VERSION ""

NS_ :

BS_:

BU_: XXX

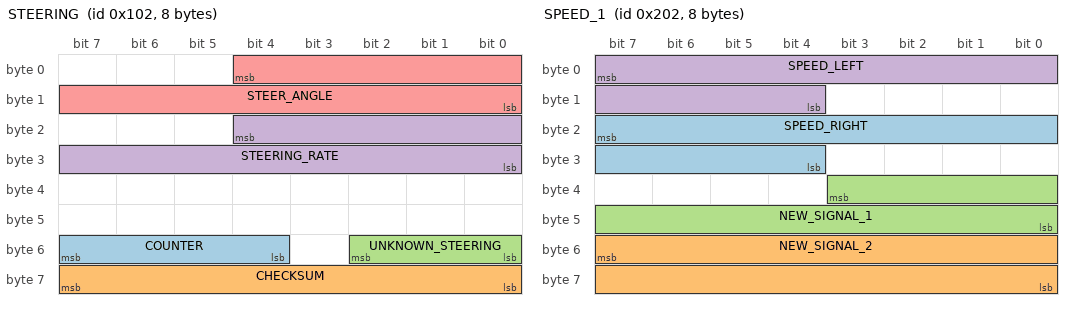
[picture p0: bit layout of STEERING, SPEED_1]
BO_ 258 STEERING: 8 XXX
 SG_ COUNTER : 55|4@0+ (1,0) [0|15] "" XXX
 SG_ CHECKSUM : 63|8@0+ (1,0) [0|255] "" XXX
 SG_ UNKNOWN_STEERING : 50|3@0+ (1,0) [0|15] "" XXX
 SG_ STEERING_RATE : 20|13@0+ (0.3187251,-1305.498) [0|8191] "deg/s" XXX
 SG_ STEER_ANGLE : 4|13@0+ (0.3187251,-1307.888) [-360|360] "deg" XXX

BO_ 514 SPEED_1: 8 XXX
 SG_ SPEED_RIGHT : 23|12@0+ (0.071028,0) [0|1023] "m/s" XXX
 SG_ NEW_SIGNAL_2 : 55|16@0+ (1,0) [0|65535] "" XXX
 SG_ NEW_SIGNAL_1 : 35|12@0+ (1,0) [0|63] "" XXX
 SG_ SPEED_LEFT : 7|12@0+ (0.071028,0) [0|65535] "m/s" XXX

BO_ 653 BRAKE_MODULE: 2 XXX
 SG_ BRAKE_PRESSURE : 15|8@0+ (1,0) [0|255] "" XXX
 SG_ BRAKE_PRESSED : 4|1@0+ (1,0) [0|4] "" XXX

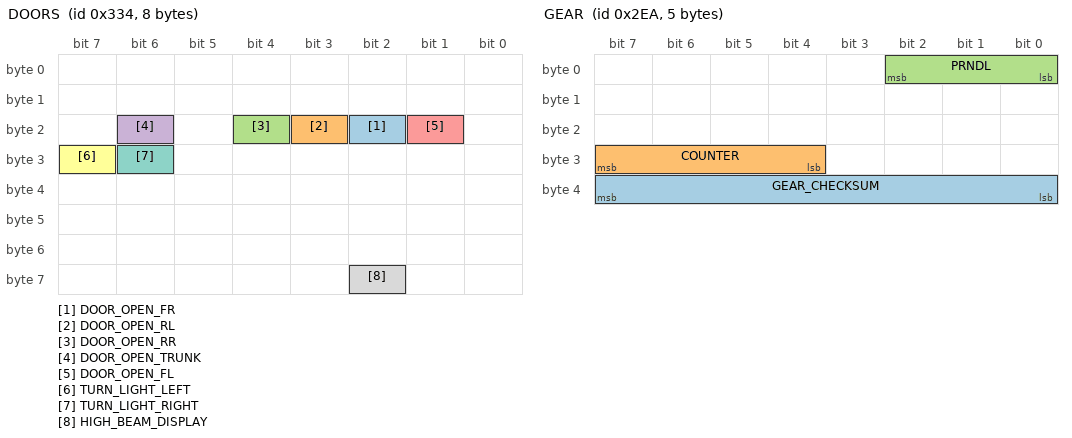
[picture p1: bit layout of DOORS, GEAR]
BO_ 820 DOORS: 8 XXX
 SG_ DOOR_OPEN_FR : 18|1@0+ (1,0) [0|1] "" XXX
 SG_ DOOR_OPEN_RL : 19|1@0+ (1,0) [0|1] "" XXX
 SG_ DOOR_OPEN_RR : 20|1@0+ (1,0) [0|1] "" XXX
 SG_ DOOR_OPEN_TRUNK : 22|1@0+ (1,0) [0|1] "" XXX
 SG_ DOOR_OPEN_FL : 17|1@0+ (1,0) [0|1] "" XXX
 SG_ TURN_LIGHT_LEFT : 31|1@0+ (1,0) [0|1] "" XXX
 SG_ TURN_LIGHT_RIGHT : 30|1@0+ (1,0) [0|1] "" XXX
 SG_ HIGH_BEAM_DISPLAY : 58|1@0+ (1,0) [0|1] "" XXX

BO_ 746 GEAR: 5 XXX
 SG_ GEAR_CHECKSUM : 39|8@0+ (1,0) [0|255] "" XXX
 SG_ COUNTER : 31|4@0+ (1,0) [0|15] "" XXX
 SG_ PRNDL : 2|3@0+ (1,0) [0|7] "" XXX

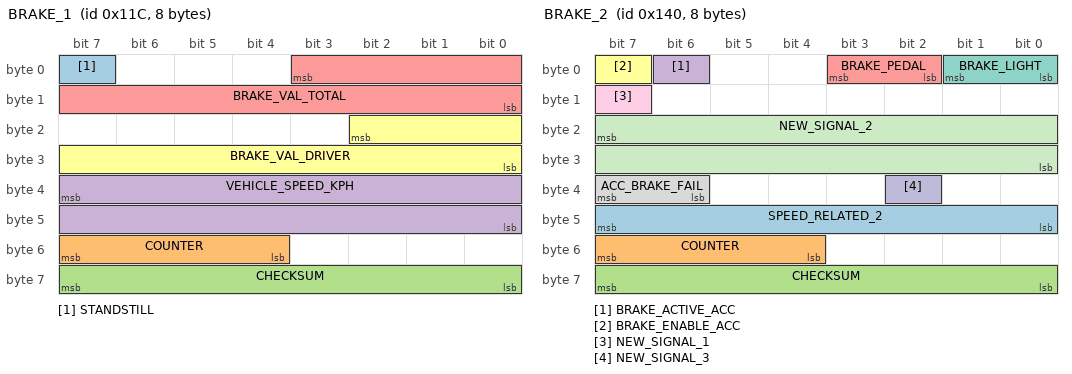
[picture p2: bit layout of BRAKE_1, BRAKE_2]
BO_ 284 BRAKE_1: 8 XXX
 SG_ STANDSTILL : 7|1@0+ (1,0) [0|1] "" XXX
 SG_ COUNTER : 55|4@0+ (1,0) [0|15] "" XXX
 SG_ CHECKSUM : 63|8@0+ (1,0) [0|255] "" XXX
 SG_ VEHICLE_SPEED_KPH : 39|16@0+ (0.0078125,0) [0|511.984375] "kph" XXX
 SG_ BRAKE_VAL_TOTAL : 3|12@0+ (1,0) [0|255] "" XXX
 SG_ BRAKE_VAL_DRIVER : 18|11@0+ (1,0) [0|255] "" XXX

BO_ 320 BRAKE_2: 8 XXX
 SG_ SPEED_RELATED_2 : 47|8@0+ (1,0) [0|63] "" XXX
 SG_ COUNTER : 55|4@0+ (1,0) [0|15] "" XXX
 SG_ CHECKSUM : 63|8@0+ (1,0) [0|255] "" XXX
 SG_ BRAKE_ACTIVE_ACC : 6|1@0+ (1,0) [0|3] "" XXX
 SG_ BRAKE_PEDAL : 2|2@1+ (1,0) [0|3] "" XXX
 SG_ BRAKE_ENABLE_ACC : 7|1@0+ (1,0) [0|1] "" XXX
 SG_ BRAKE_LIGHT : 1|2@0+ (1,0) [0|7] "" XXX
 SG_ ACC_BRAKE_FAIL : 39|2@0+ (1,0) [0|3] "" XXX
 SG_ NEW_SIGNAL_1 : 15|1@0+ (1,0) [0|255] "" XXX
 SG_ NEW_SIGNAL_3 : 34|1@0+ (1,0) [0|63] "" XXX
 SG_ NEW_SIGNAL_2 : 23|16@0+ (1,0) [0|65535] "" XXX

BO_ 736 TRIP: 8 XXX
 SG_ COUNTER : 7|16@0+ (1,0) [0|65535] "Meters" XXX
 SG_ COUNTER_2 : 23|16@0+ (1,0) [0|65535] "Meters" XXX

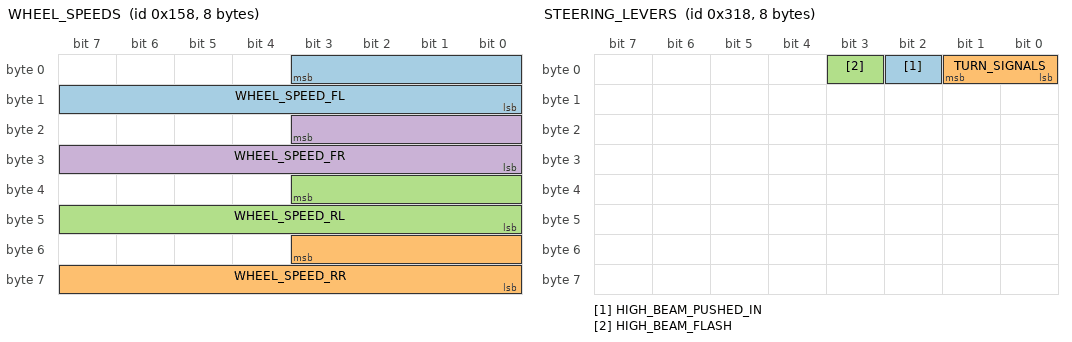
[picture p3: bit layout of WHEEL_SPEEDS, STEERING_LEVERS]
BO_ 344 WHEEL_SPEEDS: 8 XXX
 SG_ WHEEL_SPEED_FL : 3|12@0+ (0.0189408,0) [0|65535] "m/s" XXX
 SG_ WHEEL_SPEED_RR : 51|12@0+ (0.0189408,0) [0|255] "m/s" XXX
 SG_ WHEEL_SPEED_RL : 35|12@0+ (0.0189408,0) [0|3] "m/s" XXX
 SG_ WHEEL_SPEED_FR : 19|12@0+ (0.0189408,0) [0|255] "m/s" XXX

BO_ 792 STEERING_LEVERS: 8 XXX
 SG_ HIGH_BEAM_PUSHED_IN : 2|1@0+ (1,0) [0|3] "" XXX
 SG_ TURN_SIGNALS : 1|2@0+ (1,0) [0|3] "" XXX
 SG_ HIGH_BEAM_FLASH : 3|1@0+ (1,0) [0|3] "" XXX

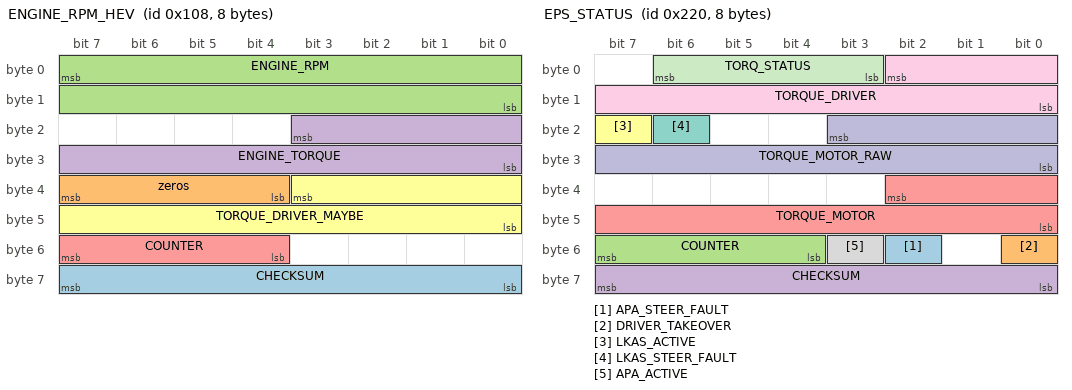
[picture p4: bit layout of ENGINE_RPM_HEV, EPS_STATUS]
BO_ 264 ENGINE_RPM_HEV: 8 XXX
 SG_ CHECKSUM : 63|8@0+ (1,0) [0|255] "" XXX
 SG_ zeros : 39|4@0+ (1,0) [0|4095] "" XXX
 SG_ ENGINE_RPM : 7|16@0+ (1,0) [0|65535] "" XXX
 SG_ ENGINE_TORQUE : 19|12@0+ (0.25,-500) [0|65535] "Nm" XXX
 SG_ COUNTER : 55|4@0+ (1,0) [0|15] "" XXX
 SG_ TORQUE_DRIVER_MAYBE : 35|12@0+ (0.25,-500) [0|1] "" XXX

BO_ 464 SEATBELT_STATUS: 8 XXX
 SG_ SEATBELT_DRIVER_UNLATCHED : 13|1@0+ (1,0) [0|1] "" XXX

BO_ 544 EPS_STATUS: 8 XXX
 SG_ APA_STEER_FAULT : 50|1@0+ (1,0) [0|1] "" XXX
 SG_ DRIVER_TAKEOVER : 48|1@0+ (1,0) [0|1] "" XXX
 SG_ COUNTER : 55|4@0+ (1,0) [0|15] "" XXX
 SG_ CHECKSUM : 63|8@0+ (1,0) [0|255] "" XXX
 SG_ TORQUE_MOTOR : 34|11@0+ (1,-1024) [0|1] "" XXX
 SG_ LKAS_ACTIVE : 23|1@0+ (1,0) [0|15] "" XXX
 SG_ LKAS_STEER_FAULT : 22|1@0+ (1,0) [0|1] "" XXX
 SG_ APA_ACTIVE : 51|1@0+ (1,0) [0|1] "" XXX
 SG_ TORQUE_DRIVER : 2|11@0+ (1,-1024) [0|1] "" XXX
 SG_ TORQUE_MOTOR_RAW : 19|12@0+ (1,-2000) [0|1] "" XXX
 SG_ TORQ_STATUS : 6|4@0+ (1,0) [0|15] "" XXX

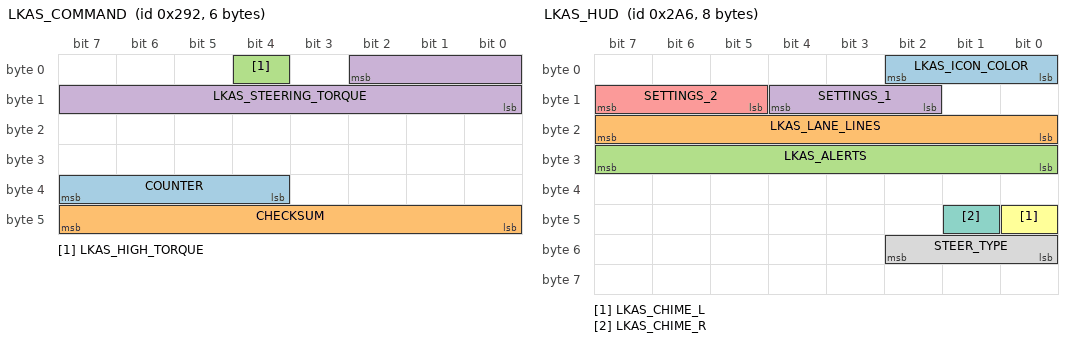
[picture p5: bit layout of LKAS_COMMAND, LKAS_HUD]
BO_ 658 LKAS_COMMAND: 6 XXX
 SG_ COUNTER : 39|4@0+ (1,0) [0|15] "" XXX
 SG_ CHECKSUM : 47|8@0+ (1,0) [0|255] "" XXX
 SG_ LKAS_HIGH_TORQUE : 4|1@0+ (1,0) [0|1] "" XXX
 SG_ LKAS_STEERING_TORQUE : 2|11@0+ (1,-1024) [0|1] "" XXX

BO_ 678 LKAS_HUD: 8 XXX
 SG_ LKAS_ICON_COLOR : 2|3@0+ (1,0) [0|3] "" XXX
 SG_ LKAS_LANE_LINES : 23|8@0+ (1,0) [0|1] "" XXX
 SG_ LKAS_ALERTS : 31|8@0+ (1,0) [0|1] "" XXX
 SG_ SETTINGS_1 : 12|3@0+ (1,0) [0|7] "" XXX
 SG_ SETTINGS_2 : 15|3@0+ (1,0) [0|31] "" XXX
 SG_ LKAS_CHIME_L : 40|1@0+ (1,0) [0|1] "" XXX
 SG_ LKAS_CHIME_R : 41|1@1+ (1,0) [0|3] "" XXX
 SG_ STEER_TYPE : 48|3@1+ (1,0) [0|3] "" XXX

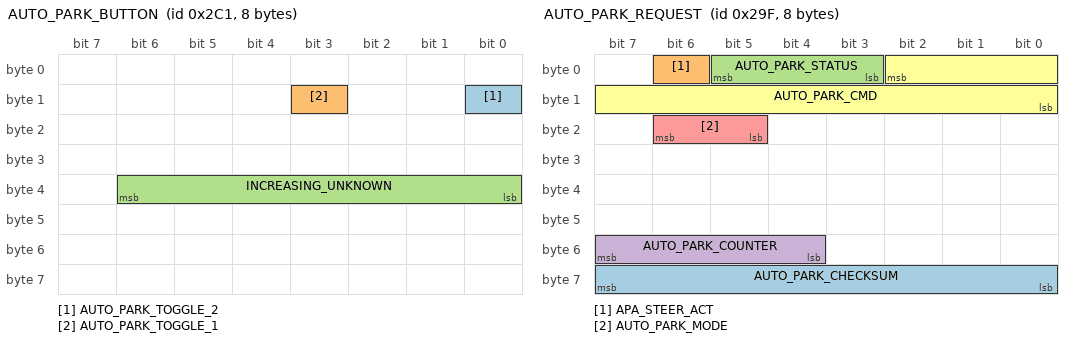
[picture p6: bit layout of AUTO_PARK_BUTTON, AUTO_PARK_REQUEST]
BO_ 705 AUTO_PARK_BUTTON: 8 XXX
 SG_ AUTO_PARK_TOGGLE_2 : 8|1@0+ (1,0) [0|1] "" XXX
 SG_ AUTO_PARK_TOGGLE_1 : 11|1@0+ (1,0) [0|1] "" XXX
 SG_ INCREASING_UNKNOWN : 38|7@0+ (1,0) [0|15] "" XXX

BO_ 719 AUTO_PARK_SIGNALS_1: 8 XXX
 SG_ AUTO_PARK_UNKNOWN_1 : 7|16@0+ (1,0) [0|31] "" XXX

BO_ 671 AUTO_PARK_REQUEST: 8 XXX
 SG_ AUTO_PARK_CHECKSUM : 63|8@0+ (1,0) [0|255] "" XXX
 SG_ APA_STEER_ACT : 6|1@0+ (1,0) [0|1] "" XXX
 SG_ AUTO_PARK_STATUS : 5|3@0+ (1,0) [0|15] "" XXX
 SG_ AUTO_PARK_COUNTER : 55|4@0+ (1,0) [0|15] "" XXX
 SG_ AUTO_PARK_MODE : 22|2@0+ (1,0) [0|3] "" XXX
 SG_ AUTO_PARK_CMD : 2|11@0+ (1,-1024) [0|1] "NM" XXX

BO_ 784 AUTO_PARK_LESS_INTERESTING: 8 XXX
 SG_ INCREASING_UNKNOWN : 55|8@0+ (1,0) [0|7] "" XXX
 SG_ AUTO_PARK_PERPENDICULAR_2 : 61|1@0+ (1,0) [0|255] "" XXX

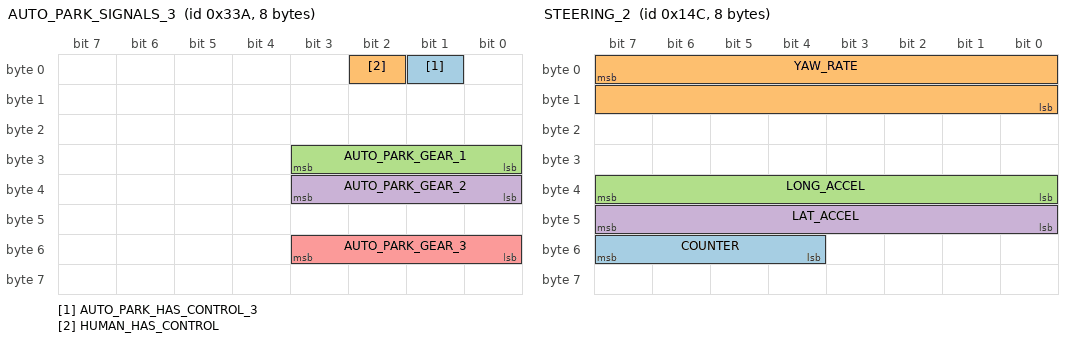
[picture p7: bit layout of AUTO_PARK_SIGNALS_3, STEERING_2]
BO_ 826 AUTO_PARK_SIGNALS_3: 8 XXX
 SG_ AUTO_PARK_HAS_CONTROL_3 : 1|1@0+ (1,0) [0|1] "" XXX
 SG_ HUMAN_HAS_CONTROL : 2|1@0+ (1,0) [0|1] "" XXX
 SG_ AUTO_PARK_GEAR_1 : 27|4@0+ (1,0) [0|255] "" XXX
 SG_ AUTO_PARK_GEAR_2 : 35|4@0+ (1,0) [0|15] "" XXX
 SG_ AUTO_PARK_GEAR_3 : 51|4@0+ (1,0) [0|15] "" XXX

BO_ 332 STEERING_2: 8 XXX
 SG_ COUNTER : 55|4@0+ (1,0) [0|15] "" XXX
 SG_ YAW_RATE : 7|16@0+ (0.01,-327.68) [-327.68|-327.66] "deg" XXX
 SG_ LONG_ACCEL : 39|8@0+ (1,0) [0|65535] "" XXX
 SG_ LAT_ACCEL : 47|8@0+ (1,0) [0|1] "" XXX

BO_ 720 BLIND_SPOT_WARNINGS: 6 XXX
 SG_ BLIND_SPOT_RIGHT : 5|1@0+ (1,0) [0|1] "" XXX
 SG_ BLIND_SPOT_LEFT : 2|1@0+ (1,0) [0|1] "" XXX

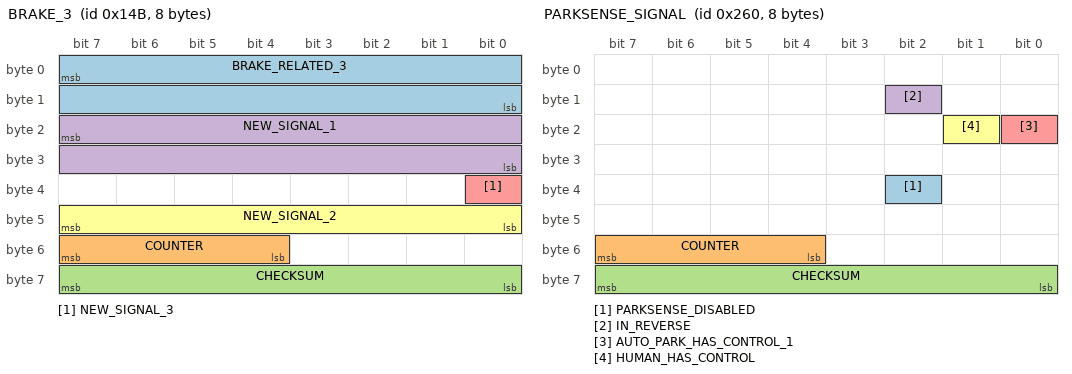
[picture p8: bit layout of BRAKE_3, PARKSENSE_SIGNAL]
BO_ 331 BRAKE_3: 8 XXX
 SG_ BRAKE_RELATED_3 : 7|16@0+ (1,0) [0|65535] "" XXX
 SG_ COUNTER : 55|4@0+ (1,0) [0|15] "" XXX
 SG_ CHECKSUM : 63|8@0+ (1,0) [0|255] "" XXX
 SG_ NEW_SIGNAL_1 : 23|16@0+ (1,0) [0|65535] "" XXX
 SG_ NEW_SIGNAL_3 : 32|1@0+ (1,0) [0|1] "" XXX
 SG_ NEW_SIGNAL_2 : 47|8@0+ (0,0) [0|65535] "" XXX

BO_ 608 PARKSENSE_SIGNAL: 8 XXX
 SG_ PARKSENSE_DISABLED : 34|1@0+ (1,0) [0|1] "" XXX
 SG_ COUNTER : 55|4@0+ (1,0) [0|15] "" XXX
 SG_ CHECKSUM : 63|8@0+ (1,0) [0|255] "" XXX
 SG_ IN_REVERSE : 10|1@0+ (1,0) [0|255] "" XXX
 SG_ AUTO_PARK_HAS_CONTROL_1 : 16|1@0+ (1,0) [0|255] "" XXX
 SG_ HUMAN_HAS_CONTROL : 17|1@0+ (1,0) [0|3] "" XXX

BO_ 729 LKAS_HEARTBIT: 5 XXX
 SG_ NEW_SIGNAL_1 : 28|3@0+ (1,0) [0|15] "" XXX
 SG_ AUTO_HIGH_BEAM : 31|1@0+ (1,0) [0|1] "" XXX
 SG_ NEW_SIGNAL_3 : 38|3@0+ (1,0) [0|7] "" XXX
 SG_ LKAS_BUTTON_LED : 24|3@1+ (1,0) [0|3] "" XXX

BO_ 274 NEW_MSG_112: 2 XXX
 SG_ NEW_SIGNAL_1 : 7|16@0+ (1,0) [0|65535] "" XXX

BO_ 290 RADIO_ECU: 6 XXX
 SG_ REMOTE_START_ACTIVATED : 6|1@0+ (1,0) [0|1] "" XXX

BO_ 376 TCM_178: 3 XXX
 SG_ NEW_SIGNAL_1 : 15|8@0+ (1,0) [0|255] "" XXX

BO_ 288 ACCEL_RELATED_120: 7 XXX
 SG_ COUNTER : 47|4@0+ (1,0) [0|15] "" XXX
 SG_ CHECKSUM : 55|8@0+ (1,0) [0|255] "" XXX
 SG_ NEW_SIGNAL_2 : 6|1@0+ (1,0) [0|1] "" XXX
 SG_ NEW_SIGNAL_3 : 7|1@0+ (1,0) [0|1] "" XXX
 SG_ ACC_ENG_OK : 5|1@0+ (1,0) [0|1] "" XXX
 SG_ TORQUE : 3|12@0+ (0.25,-500) [0|255] "" XXX
 SG_ ACCEL : 23|8@0+ (1,0) [0|255] "" XXX
 SG_ ACC_OVERRIDE : 31|1@0+ (1,0) [0|1] "" XXX
 SG_ GAS_ENGINE_RPM_MAYBE : 31|16@0+ (0.25,-500) [0|65535] "" XXX

BO_ 257 PCM_101: 5 XXX
 SG_ ENERGY_OR_RPM : 31|8@0+ (1,0) [0|255] "" XXX

BO_ 388 NEW_MSG_184: 4 XXX

BO_ 448 NEW_MSG_1c0: 6 XXX

BO_ 456 NEW_MSG_1c8: 4 XXX

BO_ 560 NEW_MSG_230: 4 XXX

BO_ 564 NEW_MSG_234: 4 XXX

BO_ 840 ACC_ERROR: 3 XXX
 SG_ ACC_ERROR : 7|16@0+ (1,0) [0|32767] "" XXX

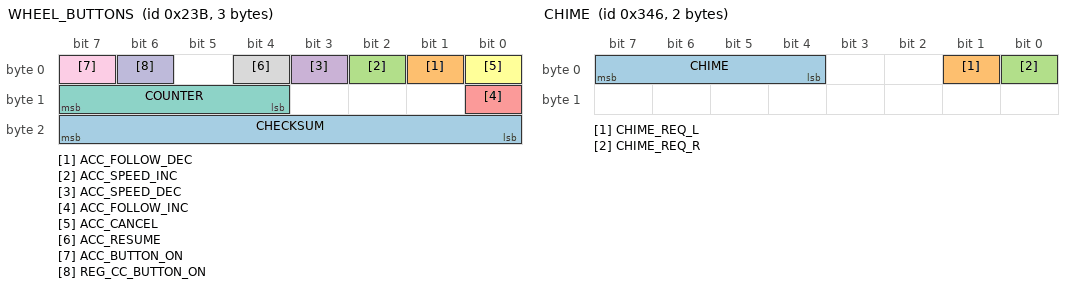
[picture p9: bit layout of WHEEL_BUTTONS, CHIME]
BO_ 571 WHEEL_BUTTONS: 3 XXX
 SG_ CHECKSUM : 23|8@0+ (1,0) [0|255] "" XXX
 SG_ ACC_FOLLOW_DEC : 1|1@0+ (1,0) [0|3] "" XXX
 SG_ ACC_SPEED_INC : 2|1@0+ (1,0) [0|255] "" XXX
 SG_ ACC_SPEED_DEC : 3|1@0+ (1,0) [0|3] "" XXX
 SG_ ACC_FOLLOW_INC : 8|1@0+ (1,0) [0|15] "" XXX
 SG_ ACC_CANCEL : 0|1@0+ (1,0) [0|15] "" XXX
 SG_ COUNTER : 15|4@0+ (1,0) [0|15] "" XXX
 SG_ ACC_RESUME : 4|1@0+ (1,0) [0|15] "" XXX
 SG_ ACC_BUTTON_ON : 7|1@0+ (1,0) [0|1] "" XXX
 SG_ REG_CC_BUTTON_ON : 6|1@0+ (1,0) [0|1] "" XXX

BO_ 669 ABS_29d: 3 XXX
 SG_ COUNTER : 15|4@0+ (1,0) [0|15] "" XXX
 SG_ CHECKSUM : 23|8@0+ (1,0) [0|255] "" XXX

BO_ 825 AUDIBLE_BEEP_339: 2 XXX
 SG_ BEEP_339 : 7|16@0+ (1,0) [0|65535] "" XXX

BO_ 856 NEW_MSG_358: 4 XXX

BO_ 860 NEW_MSG_35c: 6 XXX

BO_ 924 NEW_MSG_39c: 3 XXX

BO_ 969 NEW_MSG_3c9: 4 XXX

BO_ 974 NEW_MSG_3ce: 5 XXX

BO_ 993 PCM_3e1: 7 XXX

BO_ 838 CHIME: 2 XXX
 SG_ CHIME : 7|4@0+ (1,0) [0|15] "" XXX
 SG_ CHIME_REQ_L : 1|1@0+ (1,0) [0|1] "" XXX
 SG_ CHIME_REQ_R : 0|1@0+ (1,0) [0|1] "" XXX

BO_ 926 NEW_MSG_39e: 3 XXX

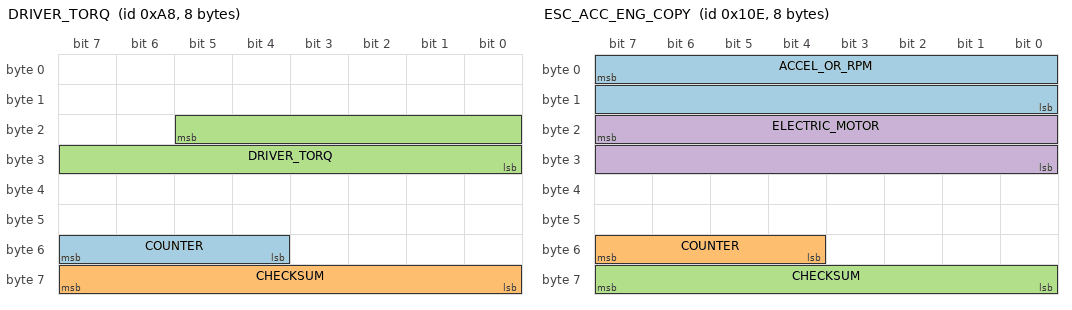
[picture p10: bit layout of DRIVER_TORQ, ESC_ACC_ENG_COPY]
BO_ 168 DRIVER_TORQ: 8 XXX
 SG_ COUNTER : 55|4@0+ (1,0) [0|15] "" XXX
 SG_ CHECKSUM : 63|8@0+ (1,0) [0|255] "" XXX
 SG_ DRIVER_TORQ : 21|14@0+ (1.5625,-4604.688) [-4604.688|20970.3125] "" XXX

BO_ 270 ESC_ACC_ENG_COPY: 8 XXX
 SG_ ACCEL_OR_RPM : 7|16@0+ (1,0) [0|255] "" XXX
 SG_ COUNTER : 55|4@0+ (1,0) [0|15] "" XXX
 SG_ CHECKSUM : 63|8@0+ (1,0) [0|255] "" XXX
 SG_ ELECTRIC_MOTOR : 23|16@0+ (1,0) [0|65535] "" XXX

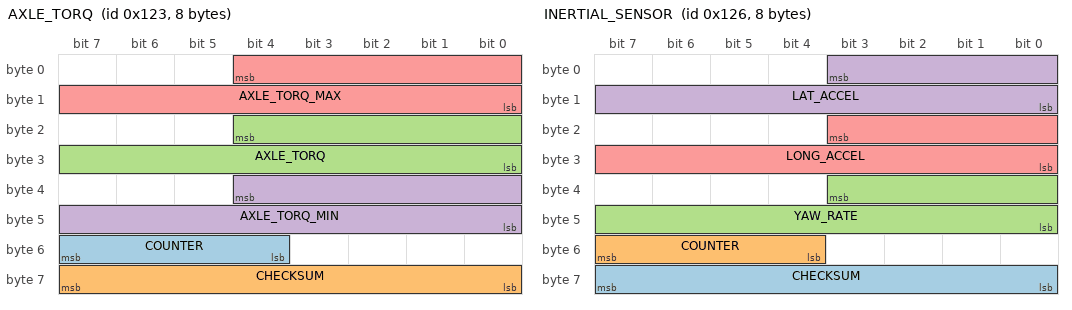
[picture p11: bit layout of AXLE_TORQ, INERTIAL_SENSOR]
BO_ 291 AXLE_TORQ: 8 XXX
 SG_ COUNTER : 55|4@0+ (1,0) [0|15] "" XXX
 SG_ CHECKSUM : 63|8@0+ (1,0) [0|255] "" XXX
 SG_ AXLE_TORQ : 20|13@0- (4,-7767) [-7767|24993] "NM" XXX
 SG_ AXLE_TORQ_MIN : 36|13@0- (4,-7767) [-7767|24993] "NM" XXX
 SG_ AXLE_TORQ_MAX : 4|13@0- (4,-7767) [-7767|24993] "NM" XXX

BO_ 294 INERTIAL_SENSOR: 8 XXX
 SG_ CHECKSUM : 63|8@0+ (1,0) [0|255] "" XXX
 SG_ COUNTER : 55|4@0+ (1,0) [0|15] "" XXX
 SG_ YAW_RATE : 35|12@0+ (1,0) [0|4095] "" XXX
 SG_ LAT_ACCEL : 3|12@0+ (1,0) [0|4095] "" XXX
 SG_ LONG_ACCEL : 19|12@0+ (0.02,-40.96) [0|2047] "m/s2" XXX

BO_ 300 NEW_MSG_12C: 8 XXX

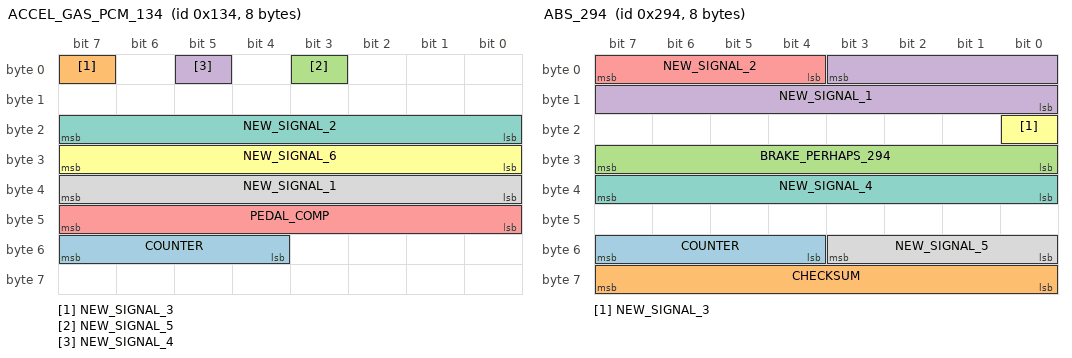
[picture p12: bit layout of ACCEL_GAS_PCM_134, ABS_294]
BO_ 308 ACCEL_GAS_PCM_134: 8 XXX
 SG_ COUNTER : 55|4@0+ (1,0) [0|15] "" XXX
 SG_ NEW_SIGNAL_3 : 7|1@0+ (1,0) [0|255] "" XXX
 SG_ NEW_SIGNAL_5 : 3|1@0+ (1,0) [0|1] "" XXX
 SG_ NEW_SIGNAL_4 : 5|1@0+ (1,0) [0|1] "" XXX
 SG_ PEDAL_COMP : 47|8@0+ (1,0) [0|127] "" XXX
 SG_ NEW_SIGNAL_6 : 24|8@1+ (1,0) [0|255] "" XXX
 SG_ NEW_SIGNAL_2 : 23|8@0+ (1,0) [0|255] "" XXX
 SG_ NEW_SIGNAL_1 : 39|8@0+ (1,0) [0|255] "" XXX

BO_ 532 ENERGY_RELATED_214: 8 XXX
 SG_ NOISY_SLOWLY_DECREASING : 16|9@0+ (1,0) [0|255] "" XXX
 SG_ ENERGY_RELATED : 0|9@0+ (1,0) [0|255] "" XXX

BO_ 559 ACCEL_GAS_PCM_22F: 8 XXX
 SG_ COUNTER : 55|4@0+ (1,0) [0|15] "" XXX
 SG_ CHECKSUM : 63|8@0+ (1,0) [0|255] "" XXX
 SG_ GAS_PEDAL_POS : 7|8@0+ (0.4,0) [0|100] "%" XXX

BO_ 655 HYBRID_ECU: 8 XXX
 SG_ CHARGING : 1|2@0+ (1,0) [0|3] "" XXX
 SG_ VEH_ON : 23|1@0+ (1,0) [0|1] "" XXX

BO_ 660 ABS_294: 8 XXX
 SG_ COUNTER : 55|4@0+ (1,0) [0|15] "" XXX
 SG_ CHECKSUM : 63|8@0+ (1,0) [0|255] "" XXX
 SG_ BRAKE_PERHAPS_294 : 31|8@0+ (1,0) [0|255] "" XXX
 SG_ NEW_SIGNAL_1 : 3|12@0+ (1,0) [0|4095] "" XXX
 SG_ NEW_SIGNAL_2 : 7|4@0+ (1,0) [0|15] "" XXX
 SG_ NEW_SIGNAL_3 : 16|1@0+ (1,0) [0|255] "" XXX
 SG_ NEW_SIGNAL_4 : 39|8@0+ (1,0) [0|255] "" XXX
 SG_ NEW_SIGNAL_5 : 48|4@1+ (1,0) [0|15] "" XXX

BO_ 764 PCM_2fc: 8 XXX
 SG_ ACCEL_2FC : 13|6@0+ (1,0) [0|255] "" XXX

BO_ 816 TRACTION_BUTTON: 8 XXX
 SG_ TRACTION_OFF : 19|1@0+ (1,0) [0|3] "" XXX
 SG_ TOGGLE_PARKSENSE : 52|1@0+ (1,0) [0|3] "" XXX

BO_ 878 HEV_POWER_USE_36E: 8 XXX
 SG_ E_MOTOR_PWR : 7|8@0+ (1,-125) [-125|130] "KW" XXX
 SG_ BATTERY_PWR_USE : 15|8@0+ (1,-125) [-126|130] "KW" XXX
 SG_ ENGINE_PWR : 49|10@0+ (1,0) [0|1023] "KW" XXX

BO_ 324 TCM_GEAR_SHIFT: 8 XXX
 SG_ GEAR : 15|4@0+ (1,0) [0|1] "" XXX
 SG_ NEW_SIGNAL_3 : 18|1@0+ (1,0) [0|1] "" XXX
 SG_ NEW_SIGNAL_4 : 20|1@0+ (1,0) [0|1] "" XXX
 SG_ NEW_SIGNAL_5 : 19|1@0+ (1,0) [0|1] "" XXX
 SG_ NEW_SIGNAL_1 : 5|1@1+ (1,0) [0|31] "" XXX
 SG_ NEW_SIGNAL_2 : 20|3@0+ (1,0) [0|15] "" XXX
 SG_ not_zero : 0|1@1+ (1,0) [0|3] "" XXX
 SG_ also_zero : 1|1@1+ (1,0) [0|3] "" XXX
 SG_ NEW_SIGNAL_6 : 17|1@0+ (1,0) [0|1] "" XXX
 SG_ NEW_SIGNAL_7 : 16|1@0+ (1,0) [0|1] "" XXX
 SG_ NEW_SIGNAL_8 : 47|4@0+ (1,0) [0|15] "" XXX
 SG_ TRANS_SPEED : 27|12@0+ (0.01,0) [0|255] "m/s" XXX
 SG_ RPM_RELATED : 43|12@0+ (1,0) [0|15] "" XXX
 SG_ NEW_SIGNAL_9 : 31|4@0+ (1,0) [0|15] "" XXX
 SG_ NEW_SIGNAL_10 : 23|3@0+ (1,0) [0|3] "" XXX
 SG_ SHIFTING : 2|1@0+ (1,0) [0|1] "" XXX
 SG_ GEAR_FINAL : 11|4@0+ (1,0) [0|1] "" XXX
 SG_ COUNTER : 63|8@0+ (1,0) [0|255] "" XXX

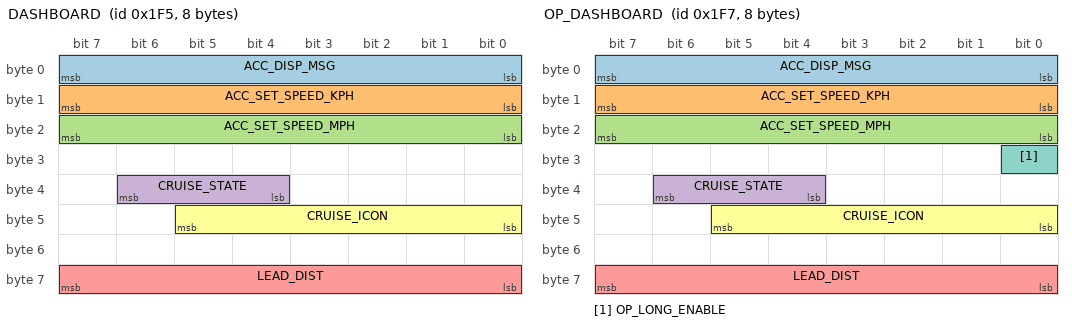
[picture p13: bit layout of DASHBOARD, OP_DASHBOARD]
BO_ 501 DASHBOARD: 8 XXX
 SG_ ACC_DISP_MSG : 7|8@0+ (1,0) [0|1] "" XXX
 SG_ ACC_SET_SPEED_KPH : 15|8@0+ (1,0) [0|255] "km/h" XXX
 SG_ ACC_SET_SPEED_MPH : 23|8@0+ (1,0) [0|255] "mph" XXX
 SG_ CRUISE_STATE : 38|3@0+ (1,0) [0|7] "" XXX
 SG_ LEAD_DIST : 63|8@0+ (1,0) [0|255] "" XXX
 SG_ CRUISE_ICON : 45|6@0+ (1,0) [0|64] "" XXX

BO_ 503 OP_DASHBOARD: 8 XXX
 SG_ ACC_DISP_MSG : 7|8@0+ (1,0) [0|1] "" XXX
 SG_ ACC_SET_SPEED_KPH : 15|8@0+ (1,0) [0|255] "km/h" XXX
 SG_ ACC_SET_SPEED_MPH : 23|8@0+ (1,0) [0|255] "mph" XXX
 SG_ CRUISE_STATE : 38|3@0+ (1,0) [0|7] "" XXX
 SG_ LEAD_DIST : 63|8@0+ (1,0) [0|255] "" XXX
 SG_ CRUISE_ICON : 45|6@0+ (1,0) [0|64] "" XXX
 SG_ OP_LONG_ENABLE : 24|1@0+ (1,0) [0|1] "" XXX

BO_ 639 NEW_MSG_27f: 8 XXX
 SG_ INCREASING : 47|8@0+ (1,0) [0|255] "" XXX

BO_ 701 NEW_MSG_2bd: 8 XXX
 SG_ unknown_1 : 39|8@0+ (1,0) [0|255] "" XXX

BO_ 832 UNKNOWN_340: 8 XXX
 SG_ SPEED_DIGITAL : 63|8@0+ (1,0) [0|255] "mph" XXX

BO_ 848 UNKNOWN_350: 8 XXX
 SG_ INCREASING_LSB : 5|6@0+ (1,0) [0|255] "" XXX
 SG_ INCREASING_MSB : 12|5@0+ (1,0) [0|31] "" XXX

BO_ 908 NEW_MSG_38c: 8 XXX
 SG_ INCREASING_MSB : 44|5@0+ (1,0) [0|31] "" XXX
 SG_ INCREASING_LSB : 61|6@0+ (1,0) [0|255] "" XXX

BO_ 938 NEW_MSG_3aa: 8 XXX
 SG_ INCREASING_UNKNOWN_1 : 39|8@0+ (1,0) [0|255] "" XXX
 SG_ INCREASING_UNKNOWN_2 : 63|8@0+ (1,0) [0|255] "" XXX

BO_ 940 NEW_MSG_3ac: 8 XXX
 SG_ INCREASING_1 : 35|4@0+ (1,0) [0|15] "" XXX
 SG_ INCREASING_2 : 63|8@0+ (1,0) [0|255] "" XXX

BO_ 941 NEW_MSG_3ad: 8 XXX
 SG_ INCREASING_1 : 36|5@0+ (1,0) [0|31] "" XXX
 SG_ INCREASING_2 : 63|8@0+ (1,0) [0|255] "" XXX

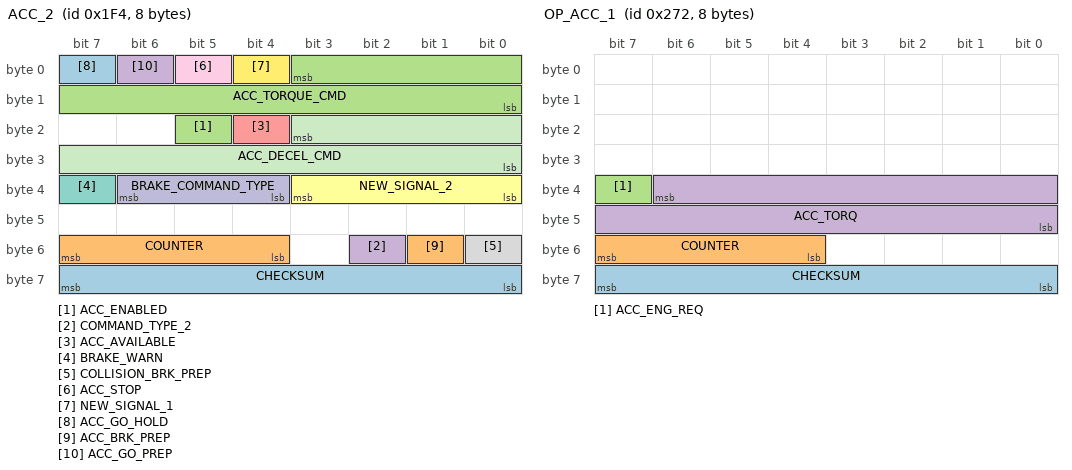
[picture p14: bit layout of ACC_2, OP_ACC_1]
BO_ 500 ACC_2: 8 XXX
 SG_ CHECKSUM : 63|8@0+ (1,0) [0|255] "" XXX
 SG_ COUNTER : 55|4@0+ (1,0) [0|15] "" XXX
 SG_ ACC_ENABLED : 21|1@0+ (1,0) [0|1] "" XXX
 SG_ COMMAND_TYPE_2 : 50|1@0+ (1,0) [0|1] "" XXX
 SG_ ACC_AVAILABLE : 20|1@0+ (1,0) [0|1] "" XXX
 SG_ NEW_SIGNAL_2 : 35|4@0+ (1,0) [0|15] "" XXX
 SG_ BRAKE_WARN : 39|1@0+ (1,0) [0|1] "" XXX
 SG_ COLLISION_BRK_PREP : 48|1@0+ (1,0) [0|1] "" XXX
 SG_ ACC_STOP : 5|1@0+ (1,0) [0|1] "" XXX
 SG_ BRAKE_COMMAND_TYPE : 38|3@0+ (1,0) [0|7] "" XXX
 SG_ ACC_DECEL_CMD : 19|12@0+ (0.004885,-16) [0|255] "m/s2" XXX
 SG_ NEW_SIGNAL_1 : 4|1@0+ (1,0) [0|1] "" XXX
 SG_ ACC_GO_HOLD : 7|1@0+ (1,0) [0|1] "" XXX
 SG_ ACC_BRK_PREP : 49|1@0+ (1,0) [0|1] "" XXX
 SG_ ACC_TORQUE_CMD : 3|12@0+ (0.25,-500) [0|255] "Nm" XXX
 SG_ ACC_GO_PREP : 6|1@0+ (1,0) [0|1] "" XXX

BO_ 502 OP_ACC_2: 8 XXX
 SG_ CHECKSUM : 63|8@0+ (1,0) [0|255] "" XXX
 SG_ COUNTER : 55|4@0+ (1,0) [0|15] "" XXX
 SG_ ACC_STOP : 5|1@0+ (1,0) [0|1] "" XXX
 SG_ ACC_AVAILABLE : 20|1@0+ (1,0) [0|1] "" XXX
 SG_ ACC_ENABLED : 21|1@0+ (1,0) [0|1] "" XXX
 SG_ BRAKE_WARN : 39|1@0+ (1,0) [0|1] "" XXX
 SG_ COLLISION_BRK_PREP : 48|1@0+ (1,0) [0|1] "" XXX
 SG_ ACC_BRK_PREP : 49|1@0+ (1,0) [0|1] "" XXX
 SG_ COMMAND_TYPE_2 : 50|0@0+ (1,0) [0|3] "" XXX
 SG_ COMMAND_TYPE : 38|3@0+ (1,0) [0|7] "" XXX
 SG_ ACC_DECEL_CMD : 19|12@0+ (0.004885,-16) [-16|4] "m/s2" XXX
 SG_ ACC_GO_PREP : 6|1@0+ (1,0) [0|1] "" XXX
 SG_ ACC_GO_HOLD : 7|1@0+ (1,0) [0|1] "" XXX
 SG_ ACC_TORQUE_CMD : 3|12@0+ (0.25,-500) [0|4095] "Nm" XXX

BO_ 625 ACC_1: 8 XXX
 SG_ COUNTER : 55|4@0+ (1,0) [0|15] "" XXX
 SG_ CHECKSUM : 63|8@0+ (1,0) [0|255] "" XXX
 SG_ zeros1 : 15|16@0+ (1,0) [0|255] "" XXX
 SG_ zeros2 : 51|4@0+ (1,0) [0|15] "" XXX
 SG_ ACC_PHEV_ENG_REQ : 39|1@0+ (1,0) [0|1] "" XXX
 SG_ const_220 : 7|8@0+ (1,0) [0|255] "" XXX
 SG_ ACC_PHEV_TORQ : 38|15@0+ (1,-7767) [-7767|24999] "NM" XXX
 SG_ VELO_REQ : 31|8@0+ (1,0) [0|255] "km/h" XXX

BO_ 626 OP_ACC_1: 8 XXX
 SG_ CHECKSUM : 63|8@0+ (1,0) [0|255] "" XXX
 SG_ COUNTER : 55|4@0+ (1,0) [0|15] "" XXX
 SG_ ACC_ENG_REQ : 39|1@0+ (1,0) [0|1] "" XXX
 SG_ ACC_TORQ : 38|15@0+ (1,-7767) [-7767|24999] "NM" XXX

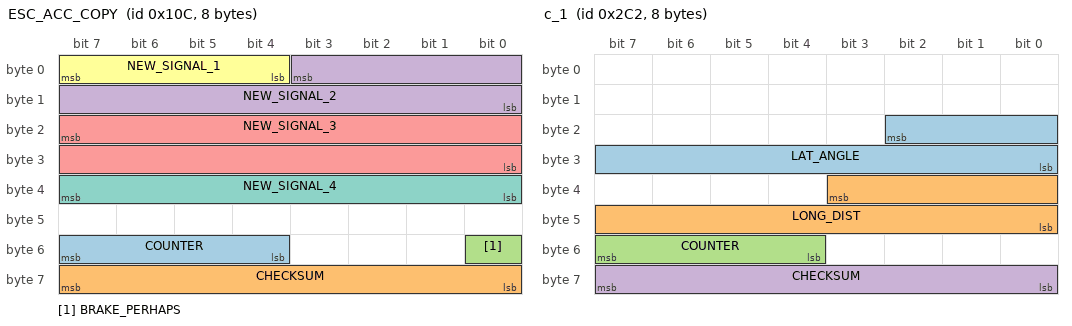
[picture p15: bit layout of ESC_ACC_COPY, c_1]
BO_ 268 ESC_ACC_COPY: 8 XXX
 SG_ COUNTER : 55|4@0+ (1,0) [0|15] "" XXX
 SG_ CHECKSUM : 63|8@0+ (1,0) [0|255] "" XXX
 SG_ BRAKE_PERHAPS : 48|1@0+ (1,0) [0|3] "" XXX
 SG_ NEW_SIGNAL_2 : 3|12@0+ (1,0) [0|255] "" XXX
 SG_ NEW_SIGNAL_3 : 23|16@0+ (1,0) [0|4095] "" XXX
 SG_ NEW_SIGNAL_1 : 7|4@0+ (1,0) [0|15] "" XXX
 SG_ NEW_SIGNAL_4 : 39|8@0+ (0,0) [0|255] "" XXX

BO_ 384 PCM_180: 8 XXX
 SG_ NEW_SIGNAL_2 : 15|8@0+ (1,0) [0|255] "" XXX
 SG_ NEW_SIGNAL_1 : 7|8@0+ (1,0) [0|255] "" XXX
 SG_ NEW_SIGNAL_3 : 39|8@0+ (1,0) [0|3] "" XXX

BO_ 853 NEW_MSG_355: 8 XXX

BO_ 939 NEW_MSG_3ab: 8 XXX

BO_ 512 NEW_MSG_200: 8 XXX
 SG_ NEW_SIGNAL_1 : 23|8@0+ (1,0) [0|255] "" XXX
 SG_ INCREASING : 27|12@0+ (1,0) [0|127] "" XXX
 SG_ COUNTER : 51|4@0+ (1,0) [0|15] "" XXX
 SG_ CHECKSUM : 63|8@0+ (1,0) [0|255] "" XXX
 SG_ NEW_SIGNAL_2 : 31|4@0+ (1,0) [0|15] "" XXX

BO_ 654 HEV_HMI: 8 XXX
 SG_ ELEC_MODE_PERCENT : 39|8@0+ (1,-100) [0|100] "%" XXX

BO_ 292 WHEEL_COUNTER: 8 XXX
 SG_ NEW_SIGNAL_1 : 7|8@0+ (1,0) [0|1] "" XXX
 SG_ NEW_SIGNAL_2 : 15|8@0+ (1,0) [0|1] "" XXX
 SG_ NEW_SIGNAL_3 : 23|8@0+ (1,0) [0|1] "" XXX
 SG_ NEW_SIGNAL_4 : 31|8@0+ (1,0) [0|1] "" XXX

BO_ 706 c_1: 8 XXX
 SG_ LAT_ANGLE : 18|11@0+ (0.00048828125,-0.5) [-0.5|0.49951171875] "" XXX
 SG_ LONG_DIST : 35|12@0+ (0.0625,0) [0|255.93752] "m" XXX
 SG_ COUNTER : 55|4@0+ (1,0) [0|15] "" XXX
 SG_ CHECKSUM : 63|8@0+ (1,0) [0|255] "" XXX

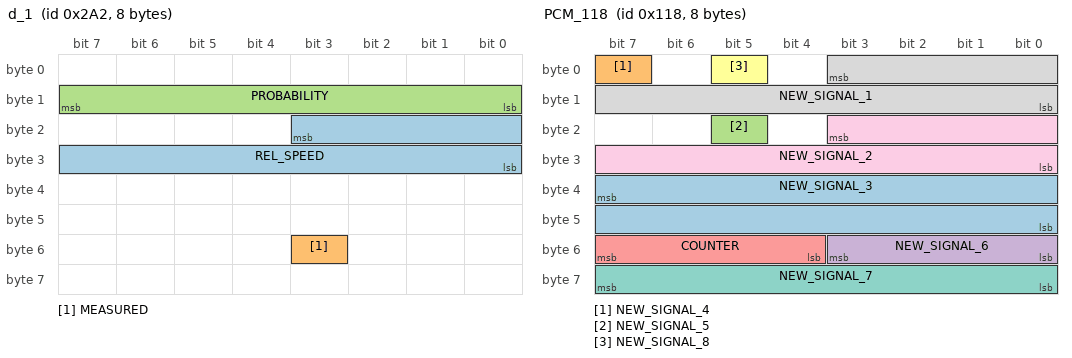
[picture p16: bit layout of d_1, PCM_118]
BO_ 674 d_1: 8 XXX
 SG_ REL_SPEED : 19|12@0+ (0.25,-128) [-128|127] "m/s" XXX
 SG_ MEASURED : 51|1@0+ (1,0) [0|1] "" XXX
 SG_ PROBABILITY : 15|8@0+ (1,0) [0|255] "" XXX

BO_ 280 PCM_118: 8 XXX
 SG_ NEW_SIGNAL_3 : 39|16@0+ (1,0) [0|255] "" XXX
 SG_ NEW_SIGNAL_4 : 7|1@0+ (1,0) [0|15] "" XXX
 SG_ NEW_SIGNAL_5 : 21|1@0+ (1,0) [0|15] "" XXX
 SG_ NEW_SIGNAL_6 : 48|4@1+ (1,0) [0|15] "" XXX
 SG_ COUNTER : 55|4@0+ (1,0) [0|1] "" XXX
 SG_ NEW_SIGNAL_8 : 5|1@0+ (1,0) [0|1] "" XXX
 SG_ NEW_SIGNAL_7 : 56|8@1+ (1,0) [0|255] "" XXX
 SG_ NEW_SIGNAL_1 : 3|12@0+ (1,0) [0|65535] "" XXX
 SG_ NEW_SIGNAL_2 : 19|12@0+ (0.25,-500) [0|63] "" XXX

BO_ 55 TCM_037: 8 XXX
 SG_ NEW_SIGNAL_4 : 39|1@0+ (1,0) [0|1] "" XXX
 SG_ NEW_SIGNAL_3 : 36|13@0+ (1,0) [0|255] "" XXX
 SG_ NEW_SIGNAL_5 : 55|4@0+ (1,0) [0|15] "" XXX
 SG_ NEW_SIGNAL_6 : 56|8@1+ (1,0) [0|255] "" XXX

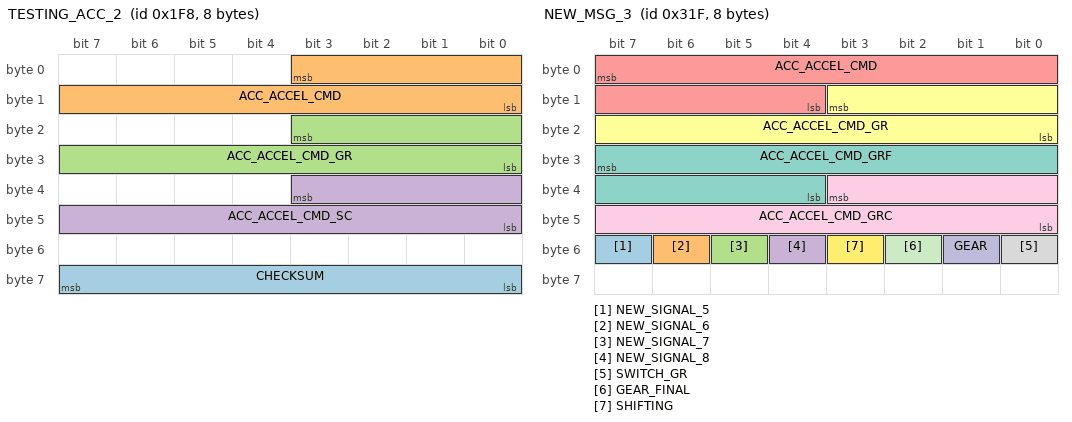
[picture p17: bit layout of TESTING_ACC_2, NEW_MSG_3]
BO_ 504 TESTING_ACC_2: 8 XXX
 SG_ CHECKSUM : 63|8@0+ (1,0) [0|255] "" XXX
 SG_ ACC_ACCEL_CMD : 3|12@0+ (1,-2000) [0|255] "" XXX
 SG_ ACC_ACCEL_CMD_GR : 19|12@0+ (1,-2000) [0|255] "" XXX
 SG_ ACC_ACCEL_CMD_SC : 35|12@0+ (0.0001,0) [0|255] "" XXX

BO_ 799 NEW_MSG_3: 8 XXX
 SG_ NEW_SIGNAL_5 : 55|1@0+ (1,0) [0|1] "" XXX
 SG_ NEW_SIGNAL_6 : 54|1@0+ (1,0) [0|1] "" XXX
 SG_ NEW_SIGNAL_7 : 53|1@0+ (1,0) [0|1] "" XXX
 SG_ NEW_SIGNAL_8 : 52|1@0+ (1,0) [0|1] "" XXX
 SG_ ACC_ACCEL_CMD : 7|12@0+ (1,0) [0|63] "" XXX
 SG_ ACC_ACCEL_CMD_GR : 11|12@0+ (1,0) [0|4095] "" XXX
 SG_ ACC_ACCEL_CMD_GRF : 31|12@0+ (1,0) [0|63] "" XXX
 SG_ SWITCH_GR : 48|1@0+ (1,0) [0|1] "" XXX
 SG_ ACC_ACCEL_CMD_GRC : 35|12@0+ (1,0) [0|4095] "" XXX
 SG_ GEAR : 49|1@0+ (1,0) [0|1] "" XXX
 SG_ GEAR_FINAL : 50|1@0+ (1,0) [0|1] "" XXX
 SG_ SHIFTING : 51|1@0+ (1,0) [0|1] "" XXX

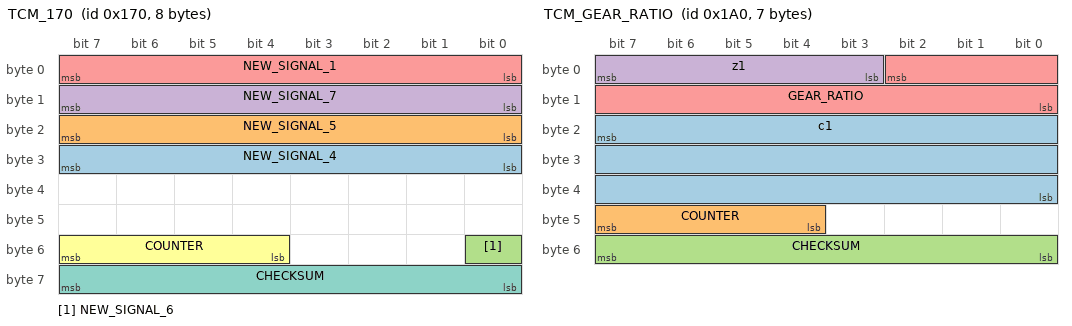
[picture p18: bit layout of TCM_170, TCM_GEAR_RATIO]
BO_ 368 TCM_170: 8 XXX
 SG_ NEW_SIGNAL_4 : 31|8@0+ (1,0) [0|65535] "" XXX
 SG_ NEW_SIGNAL_5 : 16|8@1+ (1,0) [0|255] "" XXX
 SG_ NEW_SIGNAL_6 : 48|1@1+ (1,0) [0|15] "" XXX
 SG_ NEW_SIGNAL_7 : 8|8@1+ (1,0) [0|255] "" XXX
 SG_ NEW_SIGNAL_1 : 7|8@0+ (1,0) [0|3] "" XXX
 SG_ COUNTER : 55|4@0+ (1,0) [0|15] "" XXX
 SG_ CHECKSUM : 56|8@1+ (1,0) [0|255] "" XXX

BO_ 416 TCM_GEAR_RATIO: 7 XXX
 SG_ c1 : 23|24@0+ (1,0) [0|65535] "" XXX
 SG_ COUNTER : 47|4@0+ (1,0) [0|15] "" XXX
 SG_ CHECKSUM : 55|8@0+ (1,0) [0|255] "" XXX
 SG_ z1 : 7|5@0+ (1,0) [0|31] "" XXX
 SG_ GEAR_RATIO : 2|11@0+ (0.01,0) [0|20.46] "" XXX

BO_ 520 NEW_MSG_6: 8 XXX
 SG_ NEW_SIGNAL_2 : 18|1@0+ (1,0) [0|255] "" XXX
 SG_ NEW_SIGNAL_4 : 47|8@0+ (1,0) [0|65535] "" XXX
 SG_ c : 7|16@0+ (1,0) [0|15] "" XXX
 SG_ NEW_SIGNAL_3 : 31|8@0+ (1,0) [0|255] "" XXX

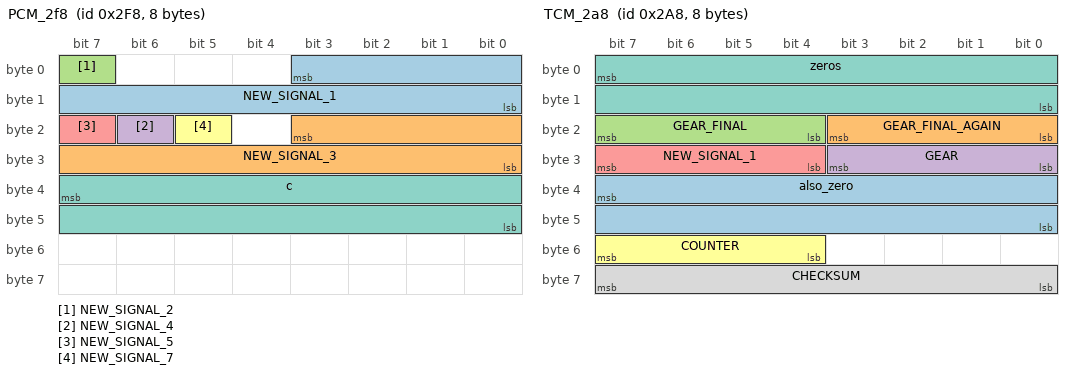
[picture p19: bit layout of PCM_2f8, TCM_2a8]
BO_ 760 PCM_2f8: 8 XXX
 SG_ NEW_SIGNAL_1 : 3|12@0+ (1,0) [0|255] "" XXX
 SG_ NEW_SIGNAL_3 : 19|12@0+ (1,0) [0|255] "" XXX
 SG_ NEW_SIGNAL_2 : 7|1@0+ (1,0) [0|15] "" XXX
 SG_ NEW_SIGNAL_4 : 22|1@0+ (1,0) [0|7] "" XXX
 SG_ NEW_SIGNAL_5 : 23|1@0+ (1,0) [0|1] "" XXX
 SG_ NEW_SIGNAL_7 : 21|1@0+ (1,0) [0|1] "" XXX
 SG_ c : 39|16@0+ (1,0) [0|255] "" XXX

BO_ 680 TCM_2a8: 8 XXX
 SG_ also_zero : 39|16@0+ (1,0) [0|65535] "" XXX
 SG_ GEAR_FINAL_AGAIN : 19|4@0+ (1,0) [0|255] "" XXX
 SG_ GEAR_FINAL : 23|4@0+ (1,0) [0|15] "" XXX
 SG_ GEAR : 24|4@1+ (1,0) [0|15] "" XXX
 SG_ NEW_SIGNAL_1 : 31|4@0+ (1,0) [0|15] "" XXX
 SG_ COUNTER : 55|4@0+ (1,0) [0|15] "" XXX
 SG_ zeros : 7|16@0+ (1,0) [0|65535] "" XXX
 SG_ CHECKSUM : 56|8@1+ (1,0) [0|255] "" XXX

BO_ 672 PCM_2a0: 8 XXX

BO_ 632 PCM_278: 8 XXX

BO_ 766 PCM_2fe: 8 XXX

BO_ 800 PCM_320: 8 XXX

BO_ 863 PCM_35f: 8 XXX

BO_ 992 PCM_3e0: 8 XXX

CM_ SG_ 258 UNKNOWN_STEERING "never goes above 4. see if human-applied torque";
CM_ SG_ 258 STEER_ANGLE "positive is left (counter-clockwise)";
CM_ SG_ 514 SPEED_LEFT "TODO find upper limit";
CM_ SG_ 653 BRAKE_PRESSURE "max seems to be 148";
CM_ SG_ 820 TURN_LIGHT_LEFT "oscillates with the light blinking";
CM_ SG_ 820 TURN_LIGHT_RIGHT "hazard blinks both right and left lights";
CM_ SG_ 746 GEAR_CHECKSUM "different than the LKAS checksum. unknown non-simple algorithm. just build a lookup table for it.";
CM_ SG_ 746 PRNDL "5=L, 4=D, 3=N, 2=R, 1=P";
CM_ SG_ 284 BRAKE_VAL_TOTAL "braking torque/pressure total";
CM_ SG_ 284 BRAKE_VAL_DRIVER "braking torque/pressure from driver";
CM_ SG_ 320 BRAKE_ACTIVE_ACC "set when ACC brakes";
CM_ SG_ 320 BRAKE_PEDAL "1= PRESSED";
CM_ SG_ 320 BRAKE_LIGHT "1 = braking";
CM_ SG_ 792 TURN_SIGNALS "1=Left, 2=Right";
CM_ SG_ 792 HIGH_BEAM_FLASH "use this for genericToggle";
CM_ SG_ 264 TORQUE_DRIVER_MAYBE "partial torque from driver gas? zero during acc torque, though matches acc when driver is letting off brakes";
CM_ SG_ 544 TORQUE_MOTOR_RAW "has larger range than TORQUE_MOTOR but ut seems biased";
CM_ SG_ 658 COUNTER "each message increments, 0..f";
CM_ SG_ 658 CHECKSUM "checksum calculated with https://gist.github.com/adhintz/94bf8d19b9075539f50172ab0fb24ba1";
CM_ SG_ 658 LKAS_STEERING_TORQUE "Most sent by stock system is 1024+-230. + is left. typically changes by 2 or 3 each 0.01s";
CM_ SG_ 678 LKAS_ICON_COLOR "3 is yellow, 2 is green, 1 is white, 0 is null";
CM_ SG_ 678 LKAS_LANE_LINES "0x01 transparent lines, 0x02 left white, 0x03 right white, 0x04 left yellow with car on top, 0x05 left yellow with car on top, 0x06 both white, 0x07 left yellow, 0x08 left yellow right white, 0x09 right yellow, 0x0a right yellow left white, 0x0b left yellow with car on top right white, 0x0c right yellow with car on top left white, (0x00, 0x0d, 0x0e, 0x0f) null";
CM_ SG_ 678 LKAS_ALERTS "(0x01, 0x02) lane sense off, (0x03, 0x04, 0x06) place hands on steering wheel, 0x07 lane departure detected + place hands on steering wheel, (0x08, 0x09) lane sense unavailable + clean front windshield, 0x0b lane sense and auto high beam unavailable + clean front windshield, 0x0c lane sense unavailable + service required, (0x00, 0x05, 0x0a, 0x0d, 0x0e, 0x0f) null";
CM_ SG_ 705 AUTO_PARK_TOGGLE_1 "set briefly when turning on or off self-parking";
CM_ SG_ 705 INCREASING_UNKNOWN "sometimes decreasing";
CM_ SG_ 671 AUTO_PARK_STATUS "1 = IDLE / NO REQUEST 9 = START REQUEST 10 = REQUEST MODE 11 = REQUEST MODE";
CM_ SG_ 671 AUTO_PARK_CMD "Request Appears to be in NM";
CM_ SG_ 784 INCREASING_UNKNOWN "perhaps distance traveled";
CM_ SG_ 826 AUTO_PARK_GEAR_1 "Reverse=0, Forward=f";
CM_ SG_ 826 AUTO_PARK_GEAR_2 "Reverse=0, Forward=f";
CM_ SG_ 826 AUTO_PARK_GEAR_3 "Reverse=0, Forward=f";
CM_ SG_ 720 BLIND_SPOT_RIGHT "yellow triangle alert on side view mirror when a car is in your blind spot";
CM_ SG_ 608 PARKSENSE_DISABLED "set if parksense is disabled";
CM_ SG_ 729 LKAS_BUTTON_LED "0-OFF; 1-ON; 2-BLINK";
CM_ SG_ 288 ACCEL "matches carstate.gas";
CM_ SG_ 288 GAS_ENGINE_RPM_MAYBE "lags acceleration, perhaps gas engine";
CM_ SG_ 257 ENERGY_OR_RPM "perhaps energy consumption or RPMs";
CM_ SG_ 571 CHECKSUM "standard checksum";
CM_ SG_ 571 ACC_BUTTON_ON "ACC button is pressed";
CM_ SG_ 571 REG_CC_BUTTON_ON "regular cruise control button pressed";
CM_ SG_ 825 BEEP_339 "sent every 0.5s. 0050 is no beep. To beep send 4355 or 4155. Used by ParkSense warning.";
CM_ SG_ 270 ELECTRIC_MOTOR "0x7fff indicates electric motor not in use";
CM_ SG_ 291 AXLE_TORQ "Torq delivered by engine to the wheels";
CM_ SG_ 308 PEDAL_COMP "only set when human presses accel pedal";
CM_ SG_ 532 NOISY_SLOWLY_DECREASING "perhaps battery but do not know";
CM_ SG_ 559 GAS_PEDAL_POS "Accel Pedal Position in %";
CM_ SG_ 816 TRACTION_OFF "set when traction off button is enabled";
CM_ SG_ 816 TOGGLE_PARKSENSE "sending 3000071ec0ff9000 enables or disables parksense";
CM_ SG_ 324 GEAR "R=11; D=1; N=0; P=13; ";
CM_ SG_ 324 TRANS_SPEED "possible transmission output shift speed?";
CM_ SG_ 324 GEAR_FINAL "R=11; D=1; N=0; P=13; ";
CM_ SG_ 324 COUNTER "increments by 4";
CM_ SG_ 501 ACC_SET_SPEED_KPH "speed configured for ACC";
CM_ SG_ 501 ACC_SET_SPEED_MPH "speed configured for ACC";
CM_ SG_ 501 CRUISE_ICON "0,1 - off; 2.3.4,5-White + distance set; 8,9,10,11-Green + no lead + distance set; 12,13,14,15- Green + lead + distance set; 34-regularCC White;  40-regularCC Green";
CM_ SG_ 639 INCREASING "perhaps number of seconds divided by two for this drive";
CM_ SG_ 848 INCREASING_LSB "lower part of time counter";
CM_ SG_ 848 INCREASING_MSB "upper part of time counter";
CM_ SG_ 908 INCREASING_MSB "time based";
CM_ SG_ 500 COMMAND_TYPE_2 "0-NONE; 1- ACC; 2- COLLISION";
CM_ SG_ 500 BRAKE_WARN "!!BRAKE!! warining";
CM_ SG_ 500 COLLISION_BRK_PREP "seems to step brake before collision braking";
CM_ SG_ 500 ACC_STOP "1 when at standstill after acc braking";
CM_ SG_ 500 BRAKE_COMMAND_TYPE "0-NONE; 1-ACC; 2-COLLISION";
CM_ SG_ 500 ACC_GO_HOLD "1 when acc accelerating (or at least not braking)";
CM_ SG_ 500 ACC_BRK_PREP "sometimes this flag goes high just before ACC deceleration";
CM_ SG_ 500 ACC_TORQUE_CMD "Engine torque request - possibly gas only, since phev uses 271";
CM_ SG_ 500 ACC_GO_PREP "when starting from standstill, not initial gas";
CM_ SG_ 625 zeros1 "constant zero";
CM_ SG_ 625 ACC_PHEV_ENG_REQ "seems like this bit goes on when ACC is asking for engine (PHEV only)";
CM_ SG_ 625 ACC_PHEV_TORQ "seems like wheel torquest request for PHEV only. Constant for ICE";
CM_ SG_ 625 VELO_REQ "leads velocity.. doesn't update during intervention";
CM_ SG_ 268 BRAKE_PERHAPS "triggers only on ACC braking";
CM_ SG_ 384 NEW_SIGNAL_1 "set in ACC gas driving. not set in electric human. not sure about gas human driving.";
VAL_ 746 PRNDL 5 "L" 4 "D" 3 "N" 2 "R" 1 "P" ;
VAL_ 792 TURN_SIGNALS 2 "Right" 1 "Left" ;
VAL_ 501 CRUISE_STATE 0 "Off" 1 "CC On" 2 "CC Engaged" 3 "ACC On" 4 "ACC Engaged" ;
